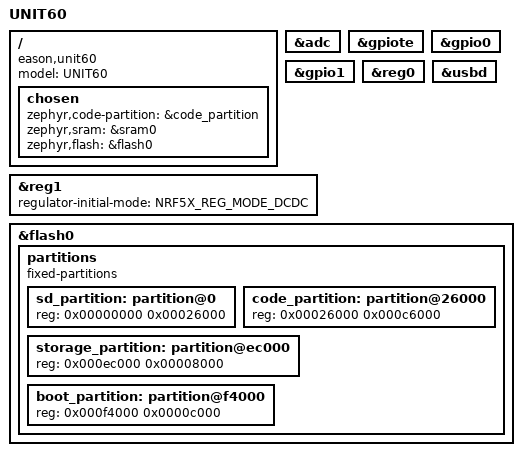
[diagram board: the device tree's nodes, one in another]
/*
 * Copyright (c) 2025 Eason
 *
 * SPDX-License-Identifier: MIT
 */

/dts-v1/;
#include <nordic/nrf52840_qiaa.dtsi>
#include <common/nordic/nrf52840_uf2_boot_mode.dtsi>

/ {
    model = "UNIT60";
    compatible = "eason,unit60";

    chosen {
        zephyr,code-partition = &code_partition;
        zephyr,sram = &sram0;
        zephyr,flash = &flash0;
    };
};

&adc {
    status = "okay";
};

&gpiote {
    status = "okay";
};

&gpio0 {
    status = "okay";
};

&gpio1 {
    status = "okay";
};

/* REG0 high-voltage DC/DC: inductor L301 between DCCH (pin 25) and VDD (pin 19).
 * VDDH (pin 23) input -> DC/DC -> VDD output. Replaces LDO (~50% eff) with DC/DC (~90% eff).
 */
&reg0 {
    status = "okay";
};

/* REG1 core DC/DC: module-internal inductor (DCC not broken out on E73-2G4M08S1C).
 * Ebyte FAQ confirms internal core DC/DC support. Verify with current measurement;
 * if current rises abnormally, remove this block.
 */
&reg1 {
    regulator-initial-mode = <NRF5X_REG_MODE_DCDC>;
};

zephyr_udc0: &usbd {
    status = "okay";
};

&flash0 {
    /*
     * For more information, see:
     * http://docs.zephyrproject.org/latest/devices/dts/flash_partitions.html
     */
    partitions {
        compatible = "fixed-partitions";
        #address-cells = <1>;
        #size-cells = <1>;

        sd_partition: partition@0 {
            reg = <0x00000000 0x00026000>;
        };
        code_partition: partition@26000 {
            reg = <0x00026000 0x000c6000>;
        };

        /*
         * The flash starting at 0x000ec000 and ending at
         * 0x000f3fff is reserved for use by the application.
         */

        /*
         * Storage partition will be used by FCB/LittleFS/NVS
         * if enabled.
         */
        storage_partition: partition@ec000 {
            reg = <0x000ec000 0x00008000>;
        };

        boot_partition: partition@f4000 {
            reg = <0x000f4000 0x0000c000>;
        };
    };
};
